# XHSC_HC32F002 register map
Vendor: XHSC Co.Ltd; Series: ARMCM0P; File version: 1.0
CPU: CM0P r0p0, little endian, no MPU, no FPU, 3 interrupt priority bits
Registers are 32-bit, read-write, reset 0x0 unless marked. A register's access mark holds for its fields unless they carry their own. Offsets are from the block's base; [hi:lo] are bit positions.

## I2C
Base 0x40000400
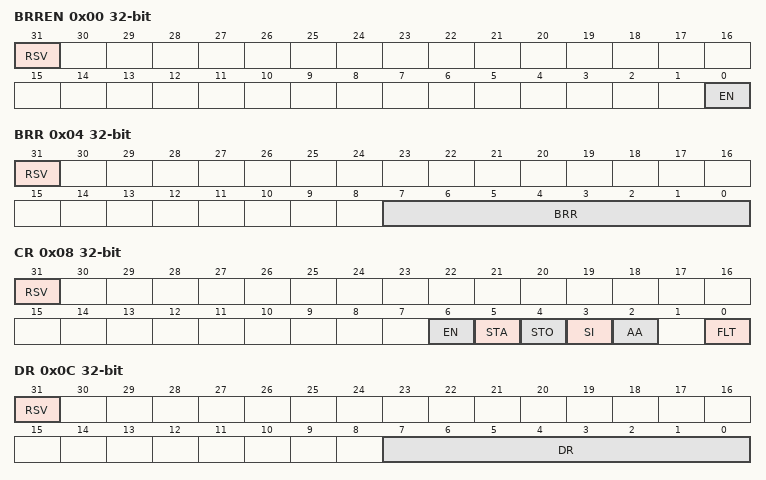
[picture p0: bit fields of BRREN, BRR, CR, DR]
0x00 BRREN (reset mask 0x1)
  [31] RSV, [0] EN
0x04 BRR (reset mask 0xFF)
  [31] RSV, [7:0] BRR
0x08 CR (reset mask 0x7D)
  [31] RSV, [6] EN, [5] STA, [4] STO, [3] SI, [2] AA, [0] FLT
0x0C DR (reset mask 0xFF)
  [31] RSV, [7:0] DR
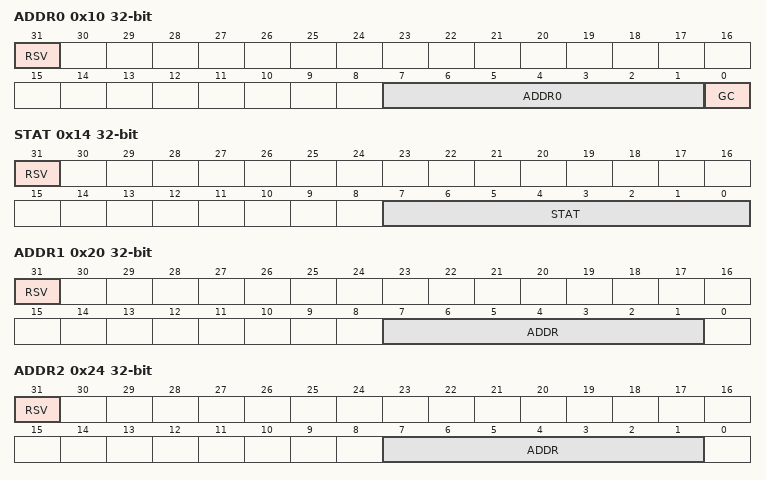
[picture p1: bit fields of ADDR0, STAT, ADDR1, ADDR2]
0x10 ADDR0 (reset mask 0xFF)
  [31] RSV, [7:1] ADDR0, [0] GC
0x14 STAT ro (reset mask 0xFF)
  [31] RSV, [7:0] STAT
0x20 ADDR1 (reset mask 0xFF)
  [31] RSV, [7:1] ADDR
0x24 ADDR2 (reset mask 0xFF)
  [31] RSV, [7:1] ADDR
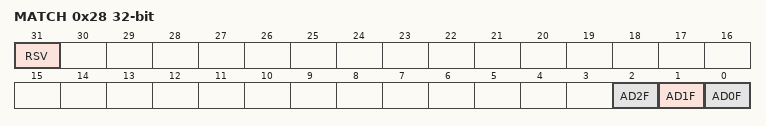
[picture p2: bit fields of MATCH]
0x28 MATCH ro (reset mask 0xFF)
  [31] RSV, [2] AD2F, [1] AD1F, [0] AD0F

## IWDT
Base 0x40000F80
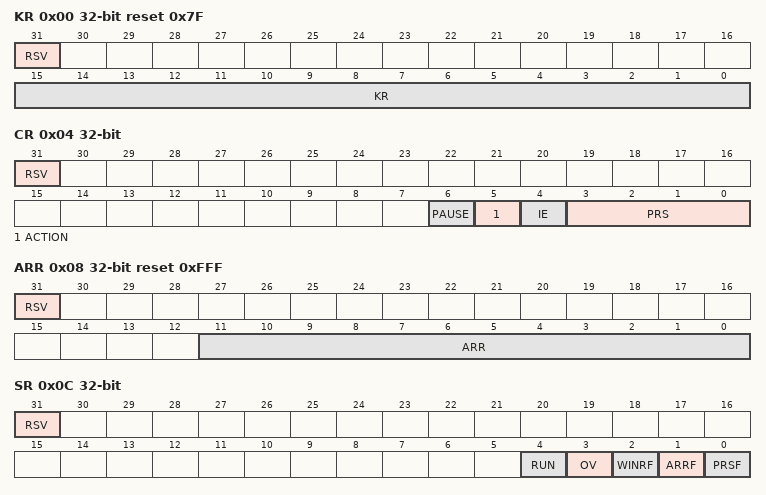
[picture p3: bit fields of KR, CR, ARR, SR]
0x00 KR wo reset 0x7F (reset mask 0xFF)
  [31] RSV, [15:0] KR
0x04 CR (reset mask 0xFF)
  [31] RSV, [6] PAUSE, [5] ACTION, [4] IE, [3:0] PRS
0x08 ARR reset 0xFFF (reset mask 0xFFF)
  [31] RSV, [11:0] ARR
0x0C SR (reset mask 0x1F)
  [31] RSV ro, [4] RUN ro, [3] OV, [2] WINRF ro, [1] ARRF ro, [0] PRSF ro
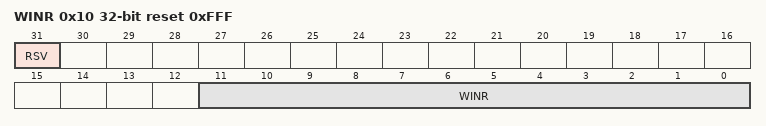
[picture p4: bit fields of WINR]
0x10 WINR reset 0xFFF (reset mask 0xFFF)
  [31] RSV, [11:0] WINR

## LPUART0 — desc LPUART
Base 0x40000000
Same registers: LPUART1 0x40004000
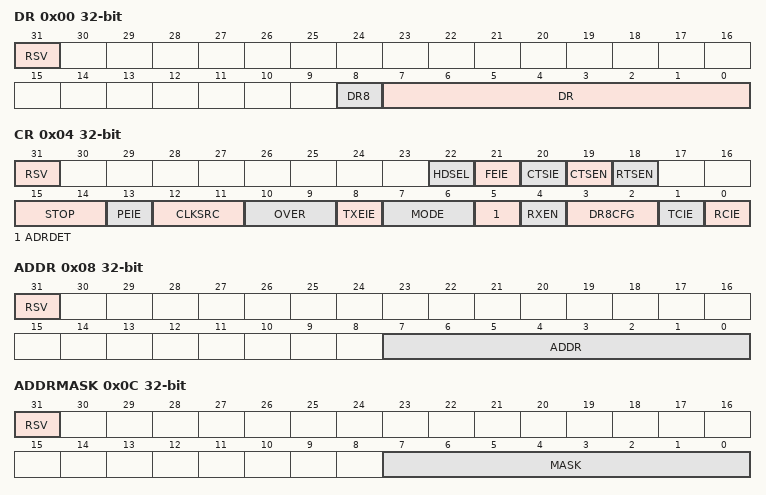
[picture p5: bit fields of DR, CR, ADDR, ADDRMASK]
0x00 DR (reset mask 0x1FF)
  [31] RSV, [8] DR8, [7:0] DR
0x04 CR (reset mask 0x7FFFFF)
  [31] RSV, [22] HDSEL, [21] FEIE, [20] CTSIE, [19] CTSEN, [18] RTSEN, [15:14] STOP, [13] PEIE, [12:11] CLKSRC, [10:9] OVER, [8] TXEIE, [7:6] MODE, [5] ADRDET, [4] RXEN, [3:2] DR8CFG, [1] TCIE, [0] RCIE
0x08 ADDR (reset mask 0xFF)
  [31] RSV, [7:0] ADDR
0x0C ADDRMASK (reset mask 0xFF)
  [31] RSV, [7:0] MASK
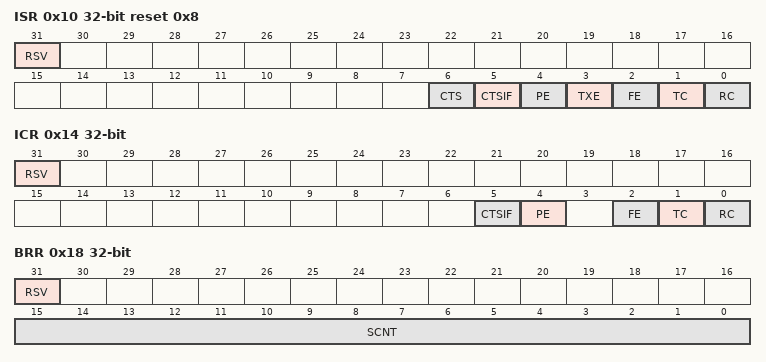
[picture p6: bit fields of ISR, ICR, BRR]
0x10 ISR ro reset 0x8 (reset mask 0x7F)
  [31] RSV rw, [6] CTS, [5] CTSIF, [4] PE, [3] TXE, [2] FE, [1] TC, [0] RC
0x14 ICR wo (reset mask 0x37)
  [31] RSV rw, [5] CTSIF, [4] PE, [2] FE, [1] TC, [0] RC
0x18 BRR (reset mask 0xFFFF)
  [31] RSV, [15:0] SCNT

## LVD
Base 0x40002680
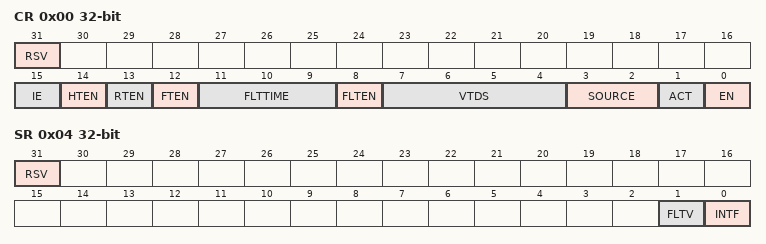
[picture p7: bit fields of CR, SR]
0x00 CR (reset mask 0xFFFF)
  [31] RSV, [15] IE, [14] HTEN, [13] RTEN, [12] FTEN, [11:9] FLTTIME, [8] FLTEN, [7:4] VTDS, [3:2] SOURCE, [1] ACT, [0] EN
0x04 SR (reset mask 0xFFFF)
  [31] RSV, [1] FLTV, [0] INTF

## SPI
Base 0x40000800
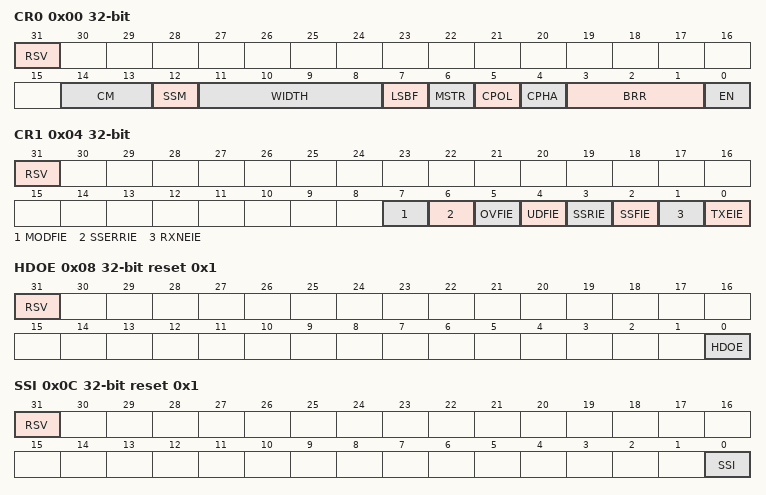
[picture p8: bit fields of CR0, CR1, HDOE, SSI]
0x00 CR0 (reset mask 0xDF)
  [31] RSV, [14:13] CM, [12] SSM, [11:8] WIDTH, [7] LSBF, [6] MSTR, [5] CPOL, [4] CPHA, [3:1] BRR, [0] EN
0x04 CR1 (reset mask 0xDF)
  [31] RSV, [7] MODFIE, [6] SSERRIE, [5] OVFIE, [4] UDFIE, [3] SSRIE, [2] SSFIE, [1] RXNEIE, [0] TXEIE
0x08 HDOE reset 0x1 (reset mask 0x1)
  [31] RSV, [0] HDOE
0x0C SSI reset 0x1 (reset mask 0x1)
  [31] RSV, [0] SSI
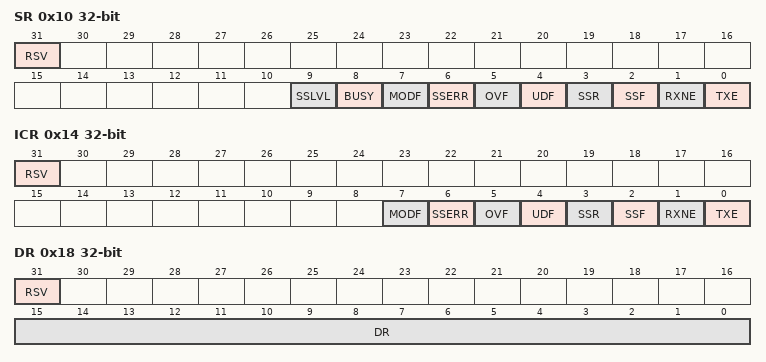
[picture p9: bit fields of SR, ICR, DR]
0x10 SR ro (reset mask 0xBE)
  [31] RSV, [9] SSLVL, [8] BUSY, [7] MODF, [6] SSERR, [5] OVF, [4] UDF, [3] SSR, [2] SSF, [1] RXNE, [0] TXE
0x14 ICR wo (reset mask 0xBE)
  [31] RSV, [7] MODF, [6] SSERR, [5] OVF, [4] UDF, [3] SSR, [2] SSF, [1] RXNE, [0] TXE
0x18 DR (reset mask 0xFF)
  [31] RSV, [15:0] DR

## SYSCTRL
Base 0x40002000
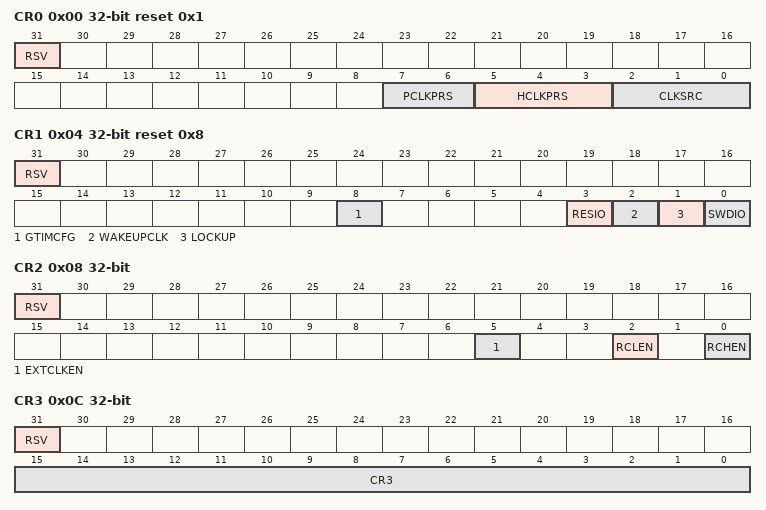
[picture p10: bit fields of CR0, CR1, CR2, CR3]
0x00 CR0 reset 0x1 (reset mask 0x9FFF)
  [31] RSV, [7:6] PCLKPRS, [5:3] HCLKPRS, [2:0] CLKSRC
0x04 CR1 reset 0x8 (reset mask 0xF7E)
  [31] RSV, [8] GTIMCFG, [3] RESIO, [2] WAKEUPCLK, [1] LOCKUP, [0] SWDIO
0x08 CR2 (reset mask 0xFFFF)
  [31] RSV, [5] EXTCLKEN, [2] RCLEN, [0] RCHEN
0x0C CR3 wo (reset mask 0xFFFF)
  [31] RSV, [15:0] CR3
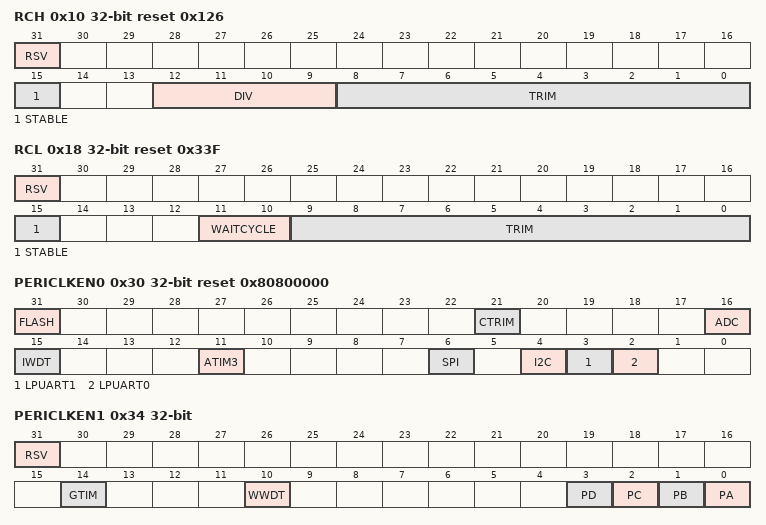
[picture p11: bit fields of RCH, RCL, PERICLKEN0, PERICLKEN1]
0x10 RCH reset 0x126 (reset mask 0xFFF)
  [31] RSV, [15] STABLE, [12:9] DIV, [8:0] TRIM
0x18 RCL reset 0x33F (reset mask 0x1FFF)
  [31] RSV, [15] STABLE, [11:10] WAITCYCLE, [9:0] TRIM
0x30 PERICLKEN0 reset 0x80800000
  [31] FLASH, [21] CTRIM, [16] ADC, [15] IWDT, [11] ATIM3, [6] SPI, [4] I2C, [3] LPUART1, [2] LPUART0
0x34 PERICLKEN1 (reset mask 0xFFF)
  [31] RSV, [14] GTIM, [10] WWDT, [3] PD, [2] PC, [1] PB, [0] PA
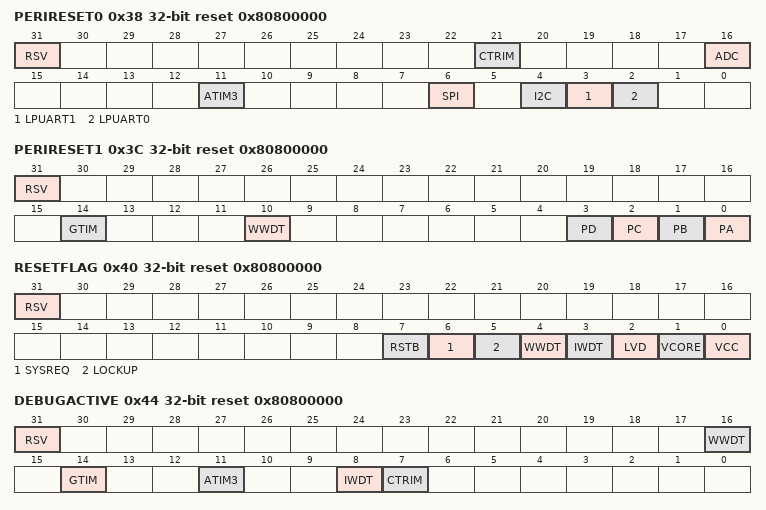
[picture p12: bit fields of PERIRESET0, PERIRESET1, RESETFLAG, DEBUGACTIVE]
0x38 PERIRESET0 reset 0x80800000
  [31] RSV, [21] CTRIM, [16] ADC, [11] ATIM3, [6] SPI, [4] I2C, [3] LPUART1, [2] LPUART0
0x3C PERIRESET1 reset 0x80800000
  [31] RSV, [14] GTIM, [10] WWDT, [3] PD, [2] PC, [1] PB, [0] PA
0x40 RESETFLAG reset 0x80800000
  [31] RSV, [7] RSTB, [6] SYSREQ, [5] LOCKUP, [4] WWDT, [3] IWDT, [2] LVD, [1] VCORE, [0] VCC
0x44 DEBUGACTIVE reset 0x80800000
  [31] RSV, [16] WWDT, [14] GTIM, [11] ATIM3, [8] IWDT, [7] CTRIM

## WWDT
Base 0x40006800
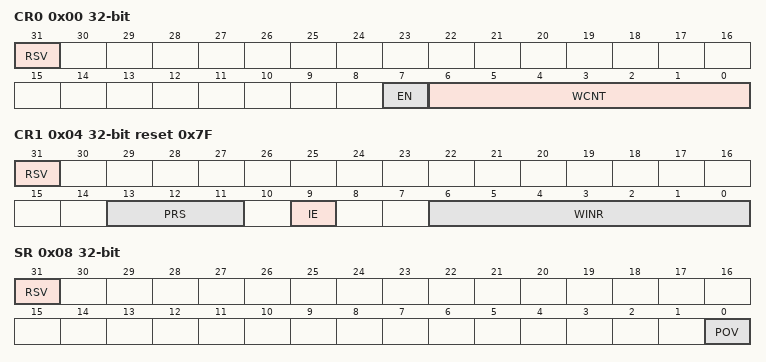
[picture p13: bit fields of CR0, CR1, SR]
0x00 CR0 (reset mask 0xFF)
  [31] RSV, [7] EN, [6:0] WCNT
0x04 CR1 reset 0x7F (reset mask 0xFF)
  [31] RSV, [13:11] PRS, [9] IE, [6:0] WINR
0x08 SR (reset mask 0x1)
  [31] RSV, [0] POV
